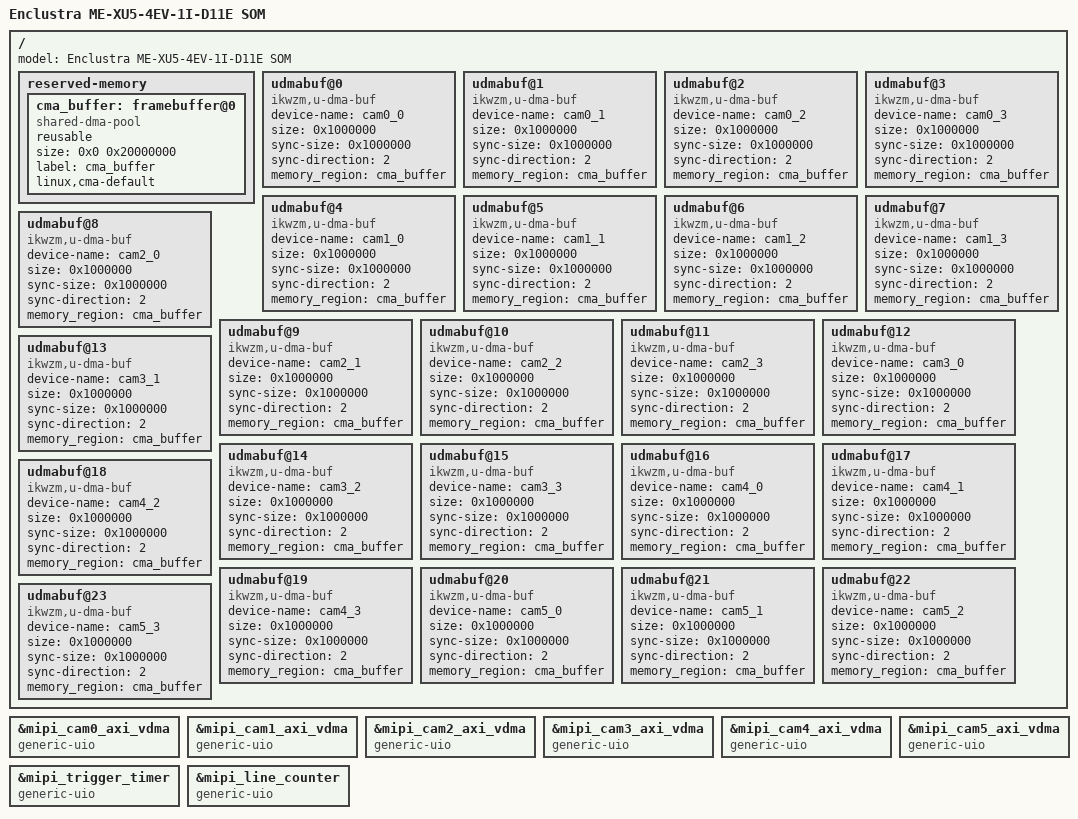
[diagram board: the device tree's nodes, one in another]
/include/ "system-conf.dtsi"
/ {
    model = "Enclustra ME-XU5-4EV-1I-D11E SOM";

  // Reference:
  //   https://xilinx-wiki.atlassian.net/wiki/spaces/A/pages/18841683/Linux+Reserved+Memory
  reserved-memory {
    #address-cells = <2>;
    #size-cells = <2>;
    ranges;

    cma_buffer: framebuffer@0 {
       compatible = "shared-dma-pool";
       reusable;
       size = <0x0 0x20000000>;
       label = "cma_buffer";
       linux,cma-default;
    };
  };

  udmabuf@0 {
    compatible = "ikwzm,u-dma-buf";
    device-name = "cam0_0";
    size = <0x1000000>; // 16 MB
    sync-size = <0x1000000>; // 16 MB
    sync-direction = <2>; // From device
    //dma-coherent; // Guaranteed cache coherency
    memory_region = <&cma_buffer>;
  };

  udmabuf@1 {
    compatible = "ikwzm,u-dma-buf";
    device-name = "cam0_1";
    size = <0x1000000>; // 16 MB
    sync-size = <0x1000000>; // 16 MB
    sync-direction = <2>; // From device
    //dma-coherent; // Guaranteed cache coherency
    memory_region = <&cma_buffer>;
  };

  udmabuf@2 {
    compatible = "ikwzm,u-dma-buf";
    device-name = "cam0_2";
    size = <0x1000000>; // 16 MB
    sync-size = <0x1000000>; // 16 MB
    sync-direction = <2>; // From device
    //dma-coherent; // Guaranteed cache coherency
    memory_region = <&cma_buffer>;
  };

  udmabuf@3 {
    compatible = "ikwzm,u-dma-buf";
    device-name = "cam0_3";
    size = <0x1000000>; // 16 MB
    sync-size = <0x1000000>; // 16 MB
    sync-direction = <2>; // From device
    //dma-coherent; // Guaranteed cache coherency
    memory_region = <&cma_buffer>;
  };

  udmabuf@4 {
    compatible = "ikwzm,u-dma-buf";
    device-name = "cam1_0";
    size = <0x1000000>; // 16 MB
    sync-size = <0x1000000>; // 16 MB
    sync-direction = <2>; // From device
    //dma-coherent; // Guaranteed cache coherency
    memory_region = <&cma_buffer>;
  };

  udmabuf@5 {
    compatible = "ikwzm,u-dma-buf";
    device-name = "cam1_1";
    size = <0x1000000>; // 16 MB
    sync-size = <0x1000000>; // 16 MB
    sync-direction = <2>; // From device
    //dma-coherent; // Guaranteed cache coherency
    memory_region = <&cma_buffer>;
  };

  udmabuf@6 {
    compatible = "ikwzm,u-dma-buf";
    device-name = "cam1_2";
    size = <0x1000000>; // 16 MB
    sync-size = <0x1000000>; // 16 MB
    sync-direction = <2>; // From device
    //dma-coherent; // Guaranteed cache coherency
    memory_region = <&cma_buffer>;
  };

  udmabuf@7 {
    compatible = "ikwzm,u-dma-buf";
    device-name = "cam1_3";
    size = <0x1000000>; // 16 MB
    sync-size = <0x1000000>; // 16 MB
    sync-direction = <2>; // From device
    //dma-coherent; // Guaranteed cache coherency
    memory_region = <&cma_buffer>;
  };

  udmabuf@8 {
    compatible = "ikwzm,u-dma-buf";
    device-name = "cam2_0";
    size = <0x1000000>; // 16 MB
    sync-size = <0x1000000>; // 16 MB
    sync-direction = <2>; // From device
    //dma-coherent; // Guaranteed cache coherency
    memory_region = <&cma_buffer>;
  };

  udmabuf@9 {
    compatible = "ikwzm,u-dma-buf";
    device-name = "cam2_1";
    size = <0x1000000>; // 16 MB
    sync-size = <0x1000000>; // 16 MB
    sync-direction = <2>; // From device
    //dma-coherent; // Guaranteed cache coherency
    memory_region = <&cma_buffer>;
  };

  udmabuf@10 {
    compatible = "ikwzm,u-dma-buf";
    device-name = "cam2_2";
    size = <0x1000000>; // 16 MB
    sync-size = <0x1000000>; // 16 MB
    sync-direction = <2>; // From device
    //dma-coherent; // Guaranteed cache coherency
    memory_region = <&cma_buffer>;
  };

  udmabuf@11 {
    compatible = "ikwzm,u-dma-buf";
    device-name = "cam2_3";
    size = <0x1000000>; // 16 MB
    sync-size = <0x1000000>; // 16 MB
    sync-direction = <2>; // From device
    //dma-coherent; // Guaranteed cache coherency
    memory_region = <&cma_buffer>;
  };

  udmabuf@12 {
    compatible = "ikwzm,u-dma-buf";
    device-name = "cam3_0";
    size = <0x1000000>; // 16 MB
    sync-size = <0x1000000>; // 16 MB
    sync-direction = <2>; // From device
    //dma-coherent; // Guaranteed cache coherency
    memory_region = <&cma_buffer>;
  };

  udmabuf@13 {
    compatible = "ikwzm,u-dma-buf";
    device-name = "cam3_1";
    size = <0x1000000>; // 16 MB
    sync-size = <0x1000000>; // 16 MB
    sync-direction = <2>; // From device
    //dma-coherent; // Guaranteed cache coherency
    memory_region = <&cma_buffer>;
  };

  udmabuf@14 {
    compatible = "ikwzm,u-dma-buf";
    device-name = "cam3_2";
    size = <0x1000000>; // 16 MB
    sync-size = <0x1000000>; // 16 MB
    sync-direction = <2>; // From device
    //dma-coherent; // Guaranteed cache coherency
    memory_region = <&cma_buffer>;
  };

  udmabuf@15 {
    compatible = "ikwzm,u-dma-buf";
    device-name = "cam3_3";
    size = <0x1000000>; // 16 MB
    sync-size = <0x1000000>; // 16 MB
    sync-direction = <2>; // From device
    //dma-coherent; // Guaranteed cache coherency
    memory_region = <&cma_buffer>;
  };

  udmabuf@16 {
    compatible = "ikwzm,u-dma-buf";
    device-name = "cam4_0";
    size = <0x1000000>; // 16 MB
    sync-size = <0x1000000>; // 16 MB
    sync-direction = <2>; // From device
    //dma-coherent; // Guaranteed cache coherency
    memory_region = <&cma_buffer>;
  };

  udmabuf@17 {
    compatible = "ikwzm,u-dma-buf";
    device-name = "cam4_1";
    size = <0x1000000>; // 16 MB
    sync-size = <0x1000000>; // 16 MB
    sync-direction = <2>; // From device
    //dma-coherent; // Guaranteed cache coherency
    memory_region = <&cma_buffer>;
  };

  udmabuf@18 {
    compatible = "ikwzm,u-dma-buf";
    device-name = "cam4_2";
    size = <0x1000000>; // 16 MB
    sync-size = <0x1000000>; // 16 MB
    sync-direction = <2>; // From device
    //dma-coherent; // Guaranteed cache coherency
    memory_region = <&cma_buffer>;
  };

  udmabuf@19 {
    compatible = "ikwzm,u-dma-buf";
    device-name = "cam4_3";
    size = <0x1000000>; // 16 MB
    sync-size = <0x1000000>; // 16 MB
    sync-direction = <2>; // From device
    //dma-coherent; // Guaranteed cache coherency
    memory_region = <&cma_buffer>;
  };

  udmabuf@20 {
    compatible = "ikwzm,u-dma-buf";
    device-name = "cam5_0";
    size = <0x1000000>; // 16 MB
    sync-size = <0x1000000>; // 16 MB
    sync-direction = <2>; // From device
    //dma-coherent; // Guaranteed cache coherency
    memory_region = <&cma_buffer>;
  };

  udmabuf@21 {
    compatible = "ikwzm,u-dma-buf";
    device-name = "cam5_1";
    size = <0x1000000>; // 16 MB
    sync-size = <0x1000000>; // 16 MB
    sync-direction = <2>; // From device
    //dma-coherent; // Guaranteed cache coherency
    memory_region = <&cma_buffer>;
  };

  udmabuf@22 {
    compatible = "ikwzm,u-dma-buf";
    device-name = "cam5_2";
    size = <0x1000000>; // 16 MB
    sync-size = <0x1000000>; // 16 MB
    sync-direction = <2>; // From device
    //dma-coherent; // Guaranteed cache coherency
    memory_region = <&cma_buffer>;
  };

  udmabuf@23 {
    compatible = "ikwzm,u-dma-buf";
    device-name = "cam5_3";
    size = <0x1000000>; // 16 MB
    sync-size = <0x1000000>; // 16 MB
    sync-direction = <2>; // From device
    //dma-coherent; // Guaranteed cache coherency
    memory_region = <&cma_buffer>;
  };

};

#include "zynqmp_enclustra_common.dtsi"
#include "zynqmp_enclustra_mercury_st1.dtsi"
#include "zynqmp_enclustra_mercury_xu5.dtsi"

// Reference:
//   https://github.com/Xilinx/linux-xlnx/blob/master/Documentation/devicetree/bindings/dma/xilinx/axi-dma.txt
&mipi_cam0_axi_vdma {
  compatible = "generic-uio";  
};

&mipi_cam1_axi_vdma {
  compatible = "generic-uio";  
};

&mipi_cam2_axi_vdma {
  compatible = "generic-uio";  
};

&mipi_cam3_axi_vdma {
  compatible = "generic-uio";  
};

&mipi_cam4_axi_vdma {
  compatible = "generic-uio";  
};

&mipi_cam5_axi_vdma {
  compatible = "generic-uio";  
};

&mipi_trigger_timer {
  compatible = "generic-uio";  
};

&mipi_line_counter {
  compatible = "generic-uio";  
};
